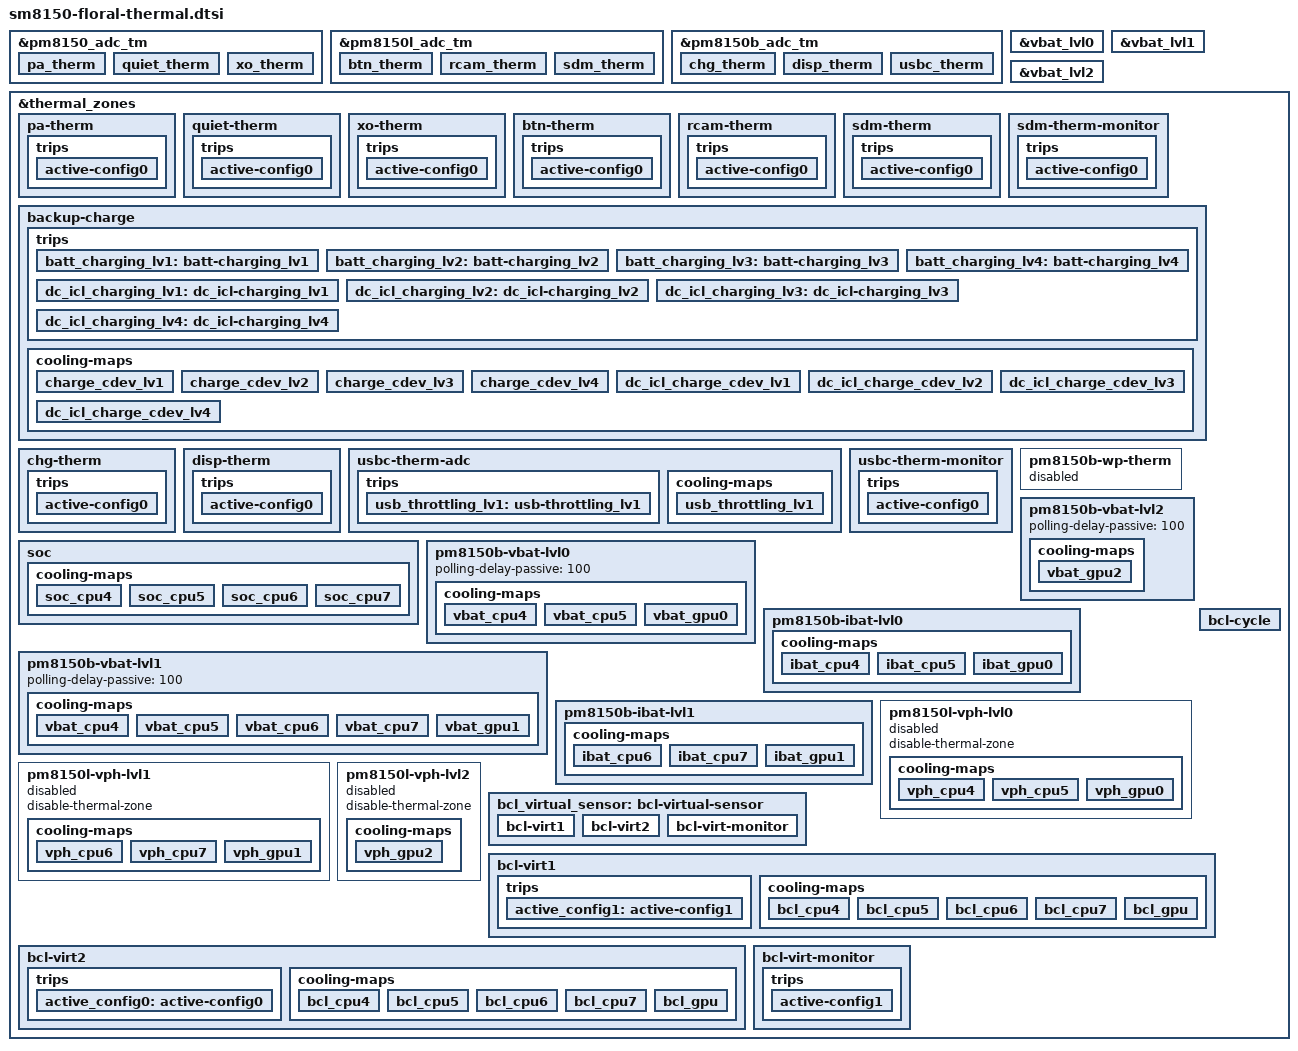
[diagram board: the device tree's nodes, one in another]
/* Copyright (c) 2018, The Linux Foundation. All rights reserved.
 *
 * This program is free software; you can redistribute it and/or modify
 * it under the terms of the GNU General Public License version 2 and
 * only version 2 as published by the Free Software Foundation.
 *
 * This program is distributed in the hope that it will be useful,
 * but WITHOUT ANY WARRANTY; without even the implied warranty of
 * MERCHANTABILITY or FITNESS FOR A PARTICULAR PURPOSE.  See the
 * GNU General Public License for more details.
 */


&pm8150_adc_tm {
	pa_therm {
		reg = <ADC_AMUX_THM2_PU2>;
		qcom,ratiometric;
		qcom,hw-settle-time = <200>;
	};

	quiet_therm {
		reg = <ADC_AMUX_THM1_PU2>;
		qcom,ratiometric;
		qcom,hw-settle-time = <200>;
	};

	xo_therm {
		reg = <ADC_XO_THERM_PU2>;
		qcom,ratiometric;
		qcom,hw-settle-time = <200>;
	};
};

&pm8150l_adc_tm {
	btn_therm {
		reg = <ADC_AMUX_THM3_PU2>;
		qcom,ratiometric;
		qcom,hw-settle-time = <200>;
	};

	rcam_therm {
		reg = <ADC_AMUX_THM1_PU2>;
		qcom,ratiometric;
		qcom,hw-settle-time = <200>;
	};

	sdm_therm {
		reg = <ADC_AMUX_THM2_PU2>;
		qcom,ratiometric;
		qcom,hw-settle-time = <200>;
	};
};

&pm8150b_adc_tm {
	io-channels = <&pm8150b_vadc ADC_AMUX_THM1_PU2>,
			<&pm8150b_vadc ADC_AMUX_THM2_PU2>,
			<&pm8150b_vadc ADC_AMUX_THM3_PU2>;

	chg_therm {
		reg = <ADC_AMUX_THM2_PU2>;
		qcom,ratiometric;
		qcom,hw-settle-time = <200>;
	};

	disp_therm {
		reg = <ADC_AMUX_THM1_PU2>;
		qcom,ratiometric;
		qcom,hw-settle-time = <200>;
	};

	usbc_therm {
		reg = <ADC_AMUX_THM3_PU2>;
		qcom,ratiometric;
		qcom,hw-settle-time = <200>;
	};
};

&vbat_lvl0 {
	temperature = <3200>;
	hysteresis = <200>;
	type = "passive";
};

&vbat_lvl1 {
	temperature = <3100>;
	hysteresis = <200>;
	type = "passive";
};

&vbat_lvl2 {
	temperature = <3000>;
	hysteresis = <200>;
	type = "passive";
};

&thermal_zones {

	pa-therm {
		polling-delay-passive = <0>;
		polling-delay = <0>;
		thermal-governor = "user_space";
		thermal-sensors = <&pm8150_adc_tm ADC_AMUX_THM2_PU2>;
		trips {
			active-config0 {
				temperature = <125000>;
				hysteresis = <1000>;
				type = "passive";
			};
		};
	};

	quiet-therm {
		polling-delay-passive = <0>;
		polling-delay = <0>;
		thermal-governor = "user_space";
		thermal-sensors = <&pm8150_adc_tm ADC_AMUX_THM1_PU2>;
		trips {
			active-config0 {
				temperature = <125000>;
				hysteresis = <1000>;
				type = "passive";
			};
		};
	};

	xo-therm {
		polling-delay-passive = <0>;
		polling-delay = <0>;
		thermal-governor = "user_space";
		thermal-sensors = <&pm8150_adc_tm ADC_XO_THERM_PU2>;
		trips {
			active-config0 {
				temperature = <125000>;
				hysteresis = <1000>;
				type = "passive";
			};
		};
	};


	btn-therm {
		polling-delay-passive = <0>;
		polling-delay = <0>;
		thermal-governor = "user_space";
		thermal-sensors = <&pm8150l_adc_tm ADC_AMUX_THM3_PU2>;
		trips {
			active-config0 {
				temperature = <125000>;
				hysteresis = <1000>;
				type = "passive";
			};
		};
	};

	rcam-therm {
		polling-delay-passive = <0>;
		polling-delay = <0>;
		thermal-governor = "user_space";
		thermal-sensors = <&pm8150l_adc_tm ADC_AMUX_THM1_PU2>;
		trips {
			active-config0 {
				temperature = <125000>;
				hysteresis = <1000>;
				type = "passive";
			};
		};
	};

	sdm-therm {
		polling-delay-passive = <0>;
		polling-delay = <0>;
		thermal-governor = "user_space";
		thermal-sensors = <&pm8150l_adc_tm ADC_AMUX_THM2_PU2>;
		trips {
			active-config0 {
				temperature = <125000>;
				hysteresis = <1000>;
				type = "passive";
			};
		};
	};

	sdm-therm-monitor {
		polling-delay-passive = <0>;
		polling-delay = <0>;
		thermal-governor = "user_space";
		thermal-sensors = <&pm8150l_adc_tm ADC_AMUX_THM2_PU2>;
		trips {
			active-config0 {
				temperature = <125000>;
				hysteresis = <1000>;
				type = "passive";
			};
		};
	};

	backup-charge {
		polling-delay-passive = <0>;
		polling-delay = <0>;
		thermal-governor = "step_wise";
		thermal-sensors = <&pm8150l_adc_tm ADC_AMUX_THM2_PU2>;
		disable-thermal-zone;
		trips {
			batt_charging_lv1: batt-charging_lv1 {
				temperature = <125000>;
				hysteresis = <1000>;
				type = "passive";
			};
			batt_charging_lv2: batt-charging_lv2 {
				temperature = <125000>;
				hysteresis = <1000>;
				type = "passive";
			};
			batt_charging_lv3: batt-charging_lv3 {
				temperature = <125000>;
				hysteresis = <1000>;
				type = "passive";
			};
			batt_charging_lv4: batt-charging_lv4 {
				temperature = <125000>;
				hysteresis = <1000>;
				type = "passive";
			};
			dc_icl_charging_lv1: dc_icl-charging_lv1 {
				temperature = <125000>;
				hysteresis = <1000>;
				type = "passive";
			};
			dc_icl_charging_lv2: dc_icl-charging_lv2 {
				temperature = <125000>;
				hysteresis = <1000>;
				type = "passive";
			};
			dc_icl_charging_lv3: dc_icl-charging_lv3 {
				temperature = <125000>;
				hysteresis = <1000>;
				type = "passive";
			};
			dc_icl_charging_lv4: dc_icl-charging_lv4 {
				temperature = <125000>;
				hysteresis = <1000>;
				type = "passive";
			};
		};

		cooling-maps {
			charge_cdev_lv1 {
				trip = <&batt_charging_lv1>;
				cooling-device = <&google_charger 1 1>;
			};
			charge_cdev_lv2 {
				trip = <&batt_charging_lv2>;
				cooling-device = <&google_charger 2 2>;
			};
			charge_cdev_lv3 {
				trip = <&batt_charging_lv3>;
				cooling-device = <&google_charger 3 3>;
			};
			charge_cdev_lv4 {
				trip = <&batt_charging_lv4>;
				cooling-device = <&google_charger 4 4>;
			};
			dc_icl_charge_cdev_lv1 {
				trip = <&dc_icl_charging_lv1>;
				cooling-device = <&google_wlc_charger 1 1>;
			};
			dc_icl_charge_cdev_lv2 {
				trip = <&dc_icl_charging_lv2>;
				cooling-device = <&google_wlc_charger 2 2>;
			};
			dc_icl_charge_cdev_lv3 {
				trip = <&dc_icl_charging_lv3>;
				cooling-device = <&google_wlc_charger 3 3>;
			};
			dc_icl_charge_cdev_lv4 {
				trip = <&dc_icl_charging_lv4>;
				cooling-device = <&google_wlc_charger 4 4>;
			};
		};
	};

	chg-therm {
		polling-delay-passive = <0>;
		polling-delay = <0>;
		thermal-governor = "user_space";
		thermal-sensors = <&pm8150b_adc_tm ADC_AMUX_THM2_PU2>;
		trips {
			active-config0 {
				temperature = <125000>;
				hysteresis = <1000>;
				type = "passive";
			};
		};
	};

	disp-therm {
		polling-delay-passive = <0>;
		polling-delay = <0>;
		thermal-governor = "user_space";
		thermal-sensors = <&pm8150b_adc_tm ADC_AMUX_THM1_PU2>;
		trips {
			active-config0 {
				temperature = <125000>;
				hysteresis = <1000>;
				type = "passive";
			};
		};
	};

	usbc-therm-adc {
		polling-delay-passive = <1000>;
		polling-delay = <0>;
		thermal-governor = "step_wise";
		thermal-sensors = <&pm8150b_adc_tm ADC_AMUX_THM3_PU2>;
		trips {
			usb_throttling_lv1: usb-throttling_lv1 {
				temperature = <55000>;
				hysteresis = <10000>;
				type = "passive";
			};
		};
		cooling-maps {
			usb_throttling_lv1 {
				trip = <&usb_throttling_lv1>;
				cooling-device =
					<&google_overheat_mitigation 1 1>;
			};
		};
	};

	usbc-therm-monitor {
		polling-delay-passive = <0>;
		polling-delay = <0>;
		thermal-governor = "user_space";
		thermal-sensors = <&pm8150b_adc_tm ADC_AMUX_THM3_PU2>;
		trips {
			active-config0 {
				temperature = <125000>;
				hysteresis = <1000>;
				type = "passive";
			};
		};
	};

	pm8150b-wp-therm {
		status = "disabled";
	};

	soc {
		cooling-maps {
			soc_cpu4 {
				trip = <&soc_trip>;
				cooling-device =
					<&CPU4 10 10>;
			};
			soc_cpu5 {
				trip = <&soc_trip>;
				cooling-device =
					<&CPU5 10 10>;
			};
			soc_cpu6 {
				trip = <&soc_trip>;
				cooling-device =
					<&CPU6 10 10>;
			};
			soc_cpu7 {
				trip = <&soc_trip>;
				cooling-device =
					<&CPU7 10 10>;
			};
		};
	};

	pm8150b-vbat-lvl0 {
		polling-delay-passive = <100>;
		cooling-maps {
			vbat_cpu4 {
				trip = <&vbat_lvl0>;
				cooling-device =
					<&CPU4 10 10>;
			};
			vbat_cpu5 {
				trip = <&vbat_lvl0>;
				cooling-device =
					<&CPU5 10 10>;
			};
			vbat_gpu0 {
				trip = <&vbat_lvl0>;
				cooling-device = <&msm_gpu 2 2>;
			};
		};
	};

	pm8150b-vbat-lvl1 {
		polling-delay-passive = <100>;
		cooling-maps {
			vbat_cpu4 {
				trip = <&vbat_lvl1>;
				cooling-device =
					<&CPU4 THERMAL_MAX_LIMIT
					THERMAL_MAX_LIMIT>;
			};
			vbat_cpu5 {
				trip = <&vbat_lvl1>;
				cooling-device =
					<&CPU5 THERMAL_MAX_LIMIT
					THERMAL_MAX_LIMIT>;
			};
			vbat_cpu6 {
				trip = <&vbat_lvl1>;
				cooling-device =
					<&CPU6 THERMAL_MAX_LIMIT
					THERMAL_MAX_LIMIT>;
			};
			vbat_cpu7 {
				trip = <&vbat_lvl1>;
				cooling-device =
					<&CPU7 THERMAL_MAX_LIMIT
					THERMAL_MAX_LIMIT>;
			};
			vbat_gpu1 {
				trip = <&vbat_lvl1>;
				cooling-device = <&msm_gpu 4 4>;
			};
		};
	};

	pm8150b-vbat-lvl2 {
		polling-delay-passive = <100>;
		cooling-maps {
			vbat_gpu2 {
				trip = <&vbat_lvl2>;
				cooling-device = <&msm_gpu THERMAL_MAX_LIMIT
							THERMAL_MAX_LIMIT>;
			};
		};
	};

	pm8150b-ibat-lvl0 {
		cooling-maps {
			ibat_cpu4 {
				trip = <&ibat_lvl0>;
				cooling-device =
					<&CPU4 10 10>;
			};
			ibat_cpu5 {
				trip = <&ibat_lvl0>;
				cooling-device =
					<&CPU5 10 10>;
			};
			ibat_gpu0 {
				trip = <&ibat_lvl0>;
				cooling-device = <&msm_gpu 2 2>;
			};
		};
	};

	pm8150b-ibat-lvl1 {
		cooling-maps {
			ibat_cpu6 {
				trip = <&ibat_lvl1>;
				cooling-device =
					<&CPU6 THERMAL_MAX_LIMIT
					THERMAL_MAX_LIMIT>;
			};
			ibat_cpu7 {
				trip = <&ibat_lvl1>;
				cooling-device =
					<&CPU7 THERMAL_MAX_LIMIT
					THERMAL_MAX_LIMIT>;
			};
			ibat_gpu1 {
				trip = <&ibat_lvl1>;
				cooling-device = <&msm_gpu 4 4>;
			};
		};
	};

	pm8150l-vph-lvl0 {
		status = "disabled";
		disable-thermal-zone;
		cooling-maps {
			vph_cpu4 {
				trip = <&vph_lvl0>;
				cooling-device =
					<&CPU4 10 10>;
			};
			vph_cpu5 {
				trip = <&vph_lvl0>;
				cooling-device =
					<&CPU5 10 10>;
			};
			vph_gpu0 {
				trip = <&vph_lvl0>;
				cooling-device = <&msm_gpu 2 2>;
			};
		};
	};

	pm8150l-vph-lvl1 {
		status = "disabled";
		disable-thermal-zone;
		cooling-maps {
			vph_cpu6 {
				trip = <&vph_lvl1>;
				cooling-device =
					<&CPU6 THERMAL_MAX_LIMIT
					THERMAL_MAX_LIMIT>;
			};
			vph_cpu7 {
				trip = <&vph_lvl1>;
				cooling-device =
					<&CPU7 THERMAL_MAX_LIMIT
					THERMAL_MAX_LIMIT>;
			};
			vph_gpu1 {
				trip = <&vph_lvl1>;
				cooling-device = <&msm_gpu 4 4>;
			};
		};
	};

	pm8150l-vph-lvl2 {
		status = "disabled";
		disable-thermal-zone;
		cooling-maps {
			vph_gpu2 {
				trip = <&vph_lvl2>;
				cooling-device = <&msm_gpu THERMAL_MAX_LIMIT
							THERMAL_MAX_LIMIT>;
			};
		};
	};

	bcl-cycle {
		polling-delay-passive = <100>;
		polling-delay = <0>;
		thermal-sensors = <&google_battery>;
	};

	bcl_virtual_sensor: bcl-virtual-sensor {
	};

	bcl-virt1 {
		polling-delay-passive = <100>;
		polling-delay = <0>;
		thermal-governor = "step_wise";
		trips {
			active_config1: active-config1 {
				temperature = <2>;
				hysteresis = <0>;
				type = "passive";
			};
		};
		cooling-maps {
			bcl_cpu4 {
				trip = <&active_config1>;
				cooling-device =
					<&CPU4 THERMAL_MAX_LIMIT
					THERMAL_MAX_LIMIT>;
			};
			bcl_cpu5 {
				trip = <&active_config1>;
				cooling-device =
					<&CPU5 THERMAL_MAX_LIMIT
					THERMAL_MAX_LIMIT>;
			};
			bcl_cpu6 {
				trip = <&active_config1>;
				cooling-device =
					<&CPU6 THERMAL_MAX_LIMIT
					THERMAL_MAX_LIMIT>;
			};
			bcl_cpu7 {
				trip = <&active_config1>;
				cooling-device =
					<&CPU7 THERMAL_MAX_LIMIT
					THERMAL_MAX_LIMIT>;
			};
			bcl_gpu {
				trip = <&active_config1>;
				cooling-device = <&msm_gpu THERMAL_MAX_LIMIT
					THERMAL_MAX_LIMIT>;
			};
		};
	};

	bcl-virt2 {
		polling-delay-passive = <100>;
		polling-delay = <0>;
		thermal-governor = "step_wise";
		trips {
			active_config0: active-config0 {
				temperature = <3>;
				hysteresis = <0>;
				type = "passive";
			};
		};
		cooling-maps {
			bcl_cpu4 {
				trip = <&active_config0>;
				cooling-device =
					<&CPU4 THERMAL_MAX_LIMIT
					THERMAL_MAX_LIMIT>;
			};
			bcl_cpu5 {
				trip = <&active_config0>;
				cooling-device =
					<&CPU5 THERMAL_MAX_LIMIT
					THERMAL_MAX_LIMIT>;
			};
			bcl_cpu6 {
				trip = <&active_config0>;
				cooling-device =
					<&CPU6 THERMAL_MAX_LIMIT
					THERMAL_MAX_LIMIT>;
			};
			bcl_cpu7 {
				trip = <&active_config0>;
				cooling-device =
					<&CPU7 THERMAL_MAX_LIMIT
					THERMAL_MAX_LIMIT>;
			};
			bcl_gpu {
				trip = <&active_config0>;
				cooling-device = <&msm_gpu THERMAL_MAX_LIMIT
					THERMAL_MAX_LIMIT>;
			};
		};
	};

	bcl-virt-monitor {
		polling-delay-passive = <0>;
		polling-delay = <0>;
		thermal-governor = "user_space";
		trips {
			active-config1 {
				temperature = <3>;
				hysteresis = <0>;
				type = "passive";
			};
		};
	};

};

&bcl_virtual_sensor {

	bcl-virt1 {
		num_sensors = <2>;
		coefficients = <(-3200) (-10000)>;
		sensor-names = "pm8150b-vbat-lvl0", "battery";
	};

	bcl-virt2 {
		num_sensors = <3>;
		coefficients = <(-3100) 400 (-10000)>;
		sensor-names = "pm8150b-vbat-lvl1", "bcl-cycle", "battery";
	};

	bcl-virt-monitor {
		num_sensors = <3>;
		coefficients = <(-3200) 400 (-10000)>;
		sensor-names = "pm8150b-vbat-lvl0", "bcl-cycle", "battery";
	};

};
